AUTOSAR XML (schema 4-0-3)
standard types defined: UInt32, UInt8
package /AUTOSAR_Platform/DataConstrs
  range DC_UInt8: raw 0..255
package /PATAC/MSM/ComponentTypes
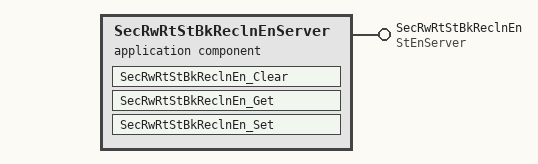
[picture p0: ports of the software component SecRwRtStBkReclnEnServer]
  application sw component type SecRwRtStBkReclnEnServer
    provide port SecRwRtStBkReclnEn: provided-com-specs=[{operation=Clear, queue-length=1}, {operation=Get, queue-length=1}, {operation=Set, queue-length=1}], provided-interface=StEnServer
    behavior SecRwRtStBkReclnEnServer_InternalBehavior
      operation invoked event OIT_SecRwRtStBkReclnEn_Clear_SecRwRtStBkReclnEn_Clear: start-on-event=SecRwRtStBkReclnEn_Clear, operation=SecRwRtStBkReclnEn.Clear
      operation invoked event OIT_SecRwRtStBkReclnEn_Get_SecRwRtStBkReclnEn_Get: start-on-event=SecRwRtStBkReclnEn_Get, operation=SecRwRtStBkReclnEn.Get
      operation invoked event OIT_SecRwRtStBkReclnEn_Set_SecRwRtStBkReclnEn_Set: start-on-event=SecRwRtStBkReclnEn_Set, operation=SecRwRtStBkReclnEn.Set
      runnable SecRwRtStBkReclnEn_Clear
      runnable SecRwRtStBkReclnEn_Get
      runnable SecRwRtStBkReclnEn_Set
  swc implementation SecRwRtStBkReclnEnServer_Implementation: behavior=SecRwRtStBkReclnEnServer_InternalBehavior
    code-descriptors:
      code Default: artifact-descriptors=autosar-engineering-object={short-label=Default, category=SWSRC}
package /PATAC/MSM/ModeAdjust/PortInterface
  client server interface StEnServer
    operation Clear
      arg data: type=UInt8, direction=IN, server-argument-impl-policy=USE-ARGUMENT-TYPE
    operation Get
      arg data: type=UInt32, direction=OUT, server-argument-impl-policy=USE-ARGUMENT-TYPE
    operation Set
      arg data: type=UInt8, direction=IN, server-argument-impl-policy=USE-ARGUMENT-TYPE
